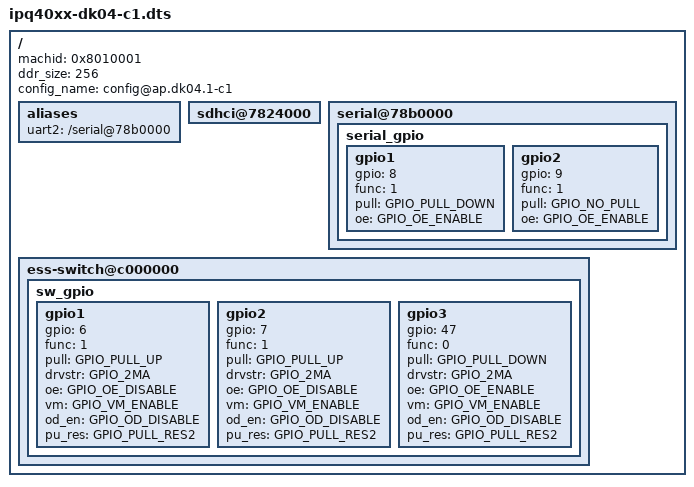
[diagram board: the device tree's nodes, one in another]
/*
 * Copyright (c) 2016, The Linux Foundation. All rights reserved.
 *
 * This program is free software; you can redistribute it and/or modify
 * it under the terms of the GNU General Public License version 2 and
 * only version 2 as published by the Free Software Foundation.
 *
 * This program is distributed in the hope that it will be useful,
 * but WITHOUT ANY WARRANTY; without even the implied warranty of
 * MERCHANTABILITY or FITNESS FOR A PARTICULAR PURPOSE.  See the
 * GNU General Public License for more details.
 */

/dts-v1/;
#include "ipq40xx-dk04.dtsi"
/ {
	machid = <0x8010001>;
	ddr_size = <256>;
	config_name = "config@ap.dk04.1-c1";

	aliases {
		uart2 = "/serial@78b0000";
	};

	sdhci@7824000 {
		status = "ok";
	};
	serial@78b0000 {
		status = "ok";
		serial_gpio {
			gpio1 {
				gpio = <8>;
				func = <1>;
				pull = <GPIO_PULL_DOWN>;
				oe = <GPIO_OE_ENABLE>;
			};

			gpio2 {
				gpio = <9>;
				func = <1>;
				pull = <GPIO_NO_PULL>;
				oe = <GPIO_OE_ENABLE>;
			};
		};
	};
	ess-switch@c000000{
		sw_gpio {
			gpio1 {
				gpio = <6>;
				func = <1>;
				pull = <GPIO_PULL_UP>;
				drvstr = <GPIO_2MA>;
				oe = <GPIO_OE_DISABLE>;
				vm = <GPIO_VM_ENABLE>;
				od_en = <GPIO_OD_DISABLE>;
				pu_res = <GPIO_PULL_RES2>;
			};

			gpio2 {
				gpio = <7>;
				func = <1>;
				pull = <GPIO_PULL_UP>;
				drvstr = <GPIO_2MA>;
				oe = <GPIO_OE_DISABLE>;
				vm = <GPIO_VM_ENABLE>;
				od_en = <GPIO_OD_DISABLE>;
				pu_res = <GPIO_PULL_RES2>;
			};

			gpio3 {
				gpio = <47>;
				func = <0>;
				pull = <GPIO_PULL_DOWN>;
				drvstr = <GPIO_2MA>;
				oe = <GPIO_OE_ENABLE>;
				vm = <GPIO_VM_ENABLE>;
				od_en = <GPIO_OD_DISABLE>;
				pu_res = <GPIO_PULL_RES2>;
			};
		};
	};

};
